# ESP32-S3 register map
Vendor: ESPRESSIF SYSTEMS (SHANGHAI) CO., LTD.; Series: ESP32 S-Series; File version: 22
CPU: Xtensa LX7 r0p0, little endian, no MPU, FPU, 0 interrupt priority bits
Address unit: 32 bits
Registers are 32-bit, read-write, reset 0x0 unless marked. A register's access mark holds for its fields unless they carry their own. Offsets are from the block's base; [hi:lo] are bit positions; {n}, {i} and the like mark numbered series.

## SPI1 — SPI (Serial Peripheral Interface) Controller 1
Base 0x60002000
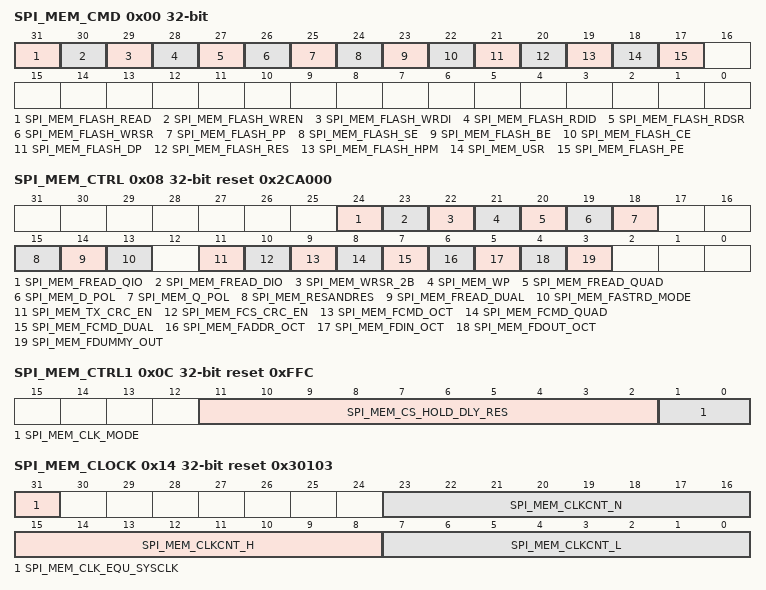
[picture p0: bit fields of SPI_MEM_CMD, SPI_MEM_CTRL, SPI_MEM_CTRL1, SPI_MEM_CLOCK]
0x00 SPI_MEM_CMD — SPI1 memory command register
  [31] SPI_MEM_FLASH_READ — Read flash enable. Read flash operation will be triggered when the bit is set. The bit will be cleared once the operation done. 1: enable 0: disable.
  [30] SPI_MEM_FLASH_WREN — Write flash enable. Write enable command will be sent when the bit is set. The bit will be cleared once the operation done. 1: enable 0: disable.
  [29] SPI_MEM_FLASH_WRDI — Write flash disable. Write disable command will be sent when the bit is set. The bit will be cleared once the operation done. 1: enable 0: disable.
  [28] SPI_MEM_FLASH_RDID — Read JEDEC ID . Read ID command will be sent when the bit is set. The bit will be cleared once the operation done. 1: enable 0: disable.
  [27] SPI_MEM_FLASH_RDSR — Read status register-1. Read status operation will be triggered when the bit is set. The bit will be cleared once the operation done.1: enable 0: disable.
  [26] SPI_MEM_FLASH_WRSR — Write status register enable. Write status operation will be triggered when the bit is set. The bit will be cleared once the operation done.1: enable 0: disable.
  [25] SPI_MEM_FLASH_PP — Page program enable(1 byte ~64 bytes data to be programmed). Page program operation will be triggered when the bit is set. The bit will be cleared once the operation done .1: enable 0: disable.
  [24] SPI_MEM_FLASH_SE — Sector erase enable(4KB). Sector erase operation will be triggered when the bit is set. The bit will be cleared once the operation done.1: enable 0: disable.
  [23] SPI_MEM_FLASH_BE — Block erase enable(32KB) . Block erase operation will be triggered when the bit is set. The bit will be cleared once the operation done.1: enable 0: disable.
  [22] SPI_MEM_FLASH_CE — Chip erase enable. Chip erase operation will be triggered when the bit is set. The bit will be cleared once the operation done.1: enable 0: disable.
  [21] SPI_MEM_FLASH_DP — Drive Flash into power down. An operation will be triggered when the bit is set. The bit will be cleared once the operation done.1: enable 0: disable.
  [20] SPI_MEM_FLASH_RES — This bit combined with SPI_MEM_RESANDRES bit releases Flash from the power-down state or high performance mode and obtains the devices ID. The bit will be cleared once the operation done.1: enable 0: disable.
  [19] SPI_MEM_FLASH_HPM — Drive Flash into high performance mode. The bit will be cleared once the operation done.1: enable 0: disable.
  [18] SPI_MEM_USR — User define command enable. An operation will be triggered when the bit is set. The bit will be cleared once the operation done.1: enable 0: disable.
  [17] SPI_MEM_FLASH_PE — In user mode, it is set to indicate that program/erase operation will be triggered. The bit is combined with SPI_MEM_USR bit. The bit will be cleared once the operation done.1: enable 0: disable.
0x04 SPI_MEM_ADDR — SPI1 address register
  [31:0] SPI_MEM_USR_ADDR_VALUE — In user mode, it is the memory address. other then the bit0-bit23 is the memory address, the bit24-bit31 are the byte length of a transfer.
0x08 SPI_MEM_CTRL reset 0x2CA000 — SPI1 control register
  [24] SPI_MEM_FREAD_QIO — In hardware 0xEB read operation, ADDR phase and DIN phase apply 4 signals(4-bit-mode). 1: enable 0: disable.
  [23] SPI_MEM_FREAD_DIO — In hardware 0xBB read operation, ADDR phase and DIN phase apply 2 signals(2-bit-mode). 1: enable 0: disable.
  [22] SPI_MEM_WRSR_2B — Two bytes data will be written to status register when it is set. 1: enable 0: disable.
  [21] SPI_MEM_WP — Write protect signal output when SPI is idle. 1: output high, 0: output low.
  [20] SPI_MEM_FREAD_QUAD — In hardware 0x6B read operation, DIN phase apply 4 signals(4-bit-mode). 1: enable 0: disable.
  [19] SPI_MEM_D_POL — The bit is used to set MOSI line polarity, 1: high 0, low
  [18] SPI_MEM_Q_POL — The bit is used to set MISO line polarity, 1: high 0, low
  [15] SPI_MEM_RESANDRES — The Device ID is read out to SPI_MEM_RD_STATUS register, this bit combine with spi_mem_flash_res bit. 1: enable 0: disable.
  [14] SPI_MEM_FREAD_DUAL — In hardware 0x3B read operation, DIN phase apply 2 signals. 1: enable 0: disable.
  [13] SPI_MEM_FASTRD_MODE — This bit should be set when SPI_MEM_FREAD_QIO, SPI_MEM_FREAD_DIO, SPI_MEM_FREAD_QUAD or SPI_MEM_FREAD_DUAL is set.
  [11] SPI_MEM_TX_CRC_EN — For SPI1, enable crc32 when writing encrypted data to flash. 1: enable 0:disable
  [10] SPI_MEM_FCS_CRC_EN — For SPI1, initialize crc32 module before writing encrypted data to flash. Active low.
  [9] SPI_MEM_FCMD_OCT — Set this bit to enable 8-bit-mode(8-bm) in CMD phase.
  [8] SPI_MEM_FCMD_QUAD — Set this bit to enable 4-bit-mode(4-bm) in CMD phase.
  [7] SPI_MEM_FCMD_DUAL — Set this bit to enable 2-bit-mode(2-bm) in CMD phase.
  [6] SPI_MEM_FADDR_OCT — Set this bit to enable 8-bit-mode(8-bm) in ADDR phase.
  [5] SPI_MEM_FDIN_OCT — Set this bit to enable 8-bit-mode(8-bm) in DIN phase.
  [4] SPI_MEM_FDOUT_OCT — Set this bit to enable 8-bit-mode(8-bm) in DOUT phase.
  [3] SPI_MEM_FDUMMY_OUT — In the DUMMY phase the signal level of SPI bus is output by the SPI0 controller.
0x0C SPI_MEM_CTRL1 reset 0xFFC — SPI1 control1 register
  [11:2] SPI_MEM_CS_HOLD_DLY_RES — After RES/DP/HPM/PES/PER command is sent, SPI1 may waits (SPI_MEM_CS_HOLD_DELAY_RES[9:0] * 4 or * 256) SPI_CLK cycles.
  [1:0] SPI_MEM_CLK_MODE — SPI Bus clock (SPI_CLK) mode bits. 0: SPI Bus clock (SPI_CLK) is off when CS inactive 1: SPI_CLK is delayed one cycle after SPI_CS inactive 2: SPI_CLK is delayed two cycles after SPI_CS inactive 3: SPI_CLK is always on.
0x10 SPI_MEM_CTRL2 — SPI1 control2 register
  [31] SPI_MEM_SYNC_RESET — The FSM will be reset.
0x14 SPI_MEM_CLOCK reset 0x30103 — SPI_CLK clock division register when SPI1 accesses to flash or Ext_RAM.
  [31] SPI_MEM_CLK_EQU_SYSCLK — When SPI1 access to flash or Ext_RAM, set this bit in 1-division mode, f_SPI_CLK = f_MSPI_CORE_CLK.
  [23:16] SPI_MEM_CLKCNT_N — When SPI1 accesses to flash or Ext_RAM, f_SPI_CLK = f_MSPI_CORE_CLK/(SPI_MEM_CLKCNT_N+1)
  [15:8] SPI_MEM_CLKCNT_H — It must be a floor value of ((SPI_MEM_CLKCNT_N+1)/2-1).
  [7:0] SPI_MEM_CLKCNT_L — It must equal to the value of SPI_MEM_CLKCNT_N.
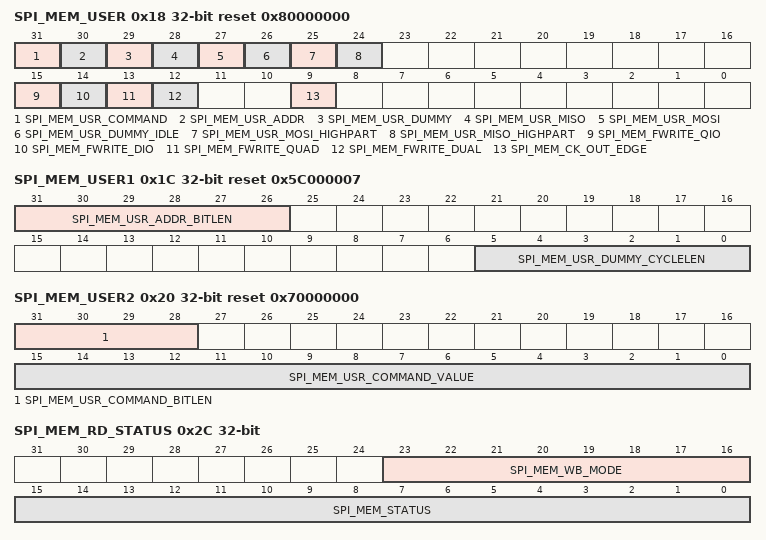
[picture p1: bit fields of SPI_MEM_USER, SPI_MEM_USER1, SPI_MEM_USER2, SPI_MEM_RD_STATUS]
0x18 SPI_MEM_USER reset 0x80000000 — SPI1 user register.
  [31] SPI_MEM_USR_COMMAND — Set this bit to enable enable the CMD phase of an operation.
  [30] SPI_MEM_USR_ADDR — Set this bit to enable enable the ADDR phase of an operation.
  [29] SPI_MEM_USR_DUMMY — Set this bit to enable enable the DUMMY phase of an operation.
  [28] SPI_MEM_USR_MISO — Set this bit to enable enable the DIN phase of a read-data operation.
  [27] SPI_MEM_USR_MOSI — Set this bit to enable the DOUT phase of an write-data operation.
  [26] SPI_MEM_USR_DUMMY_IDLE — SPI_CLK is disabled(No clock edges) in DUMMY phase when the bit is enable.
  [25] SPI_MEM_USR_MOSI_HIGHPART — DOUT phase only access to high-part of the buffer SPI_MEM_W8_REG~SPI_MEM_W15_REG. 1: enable 0: disable.
  [24] SPI_MEM_USR_MISO_HIGHPART — DIN phase only access to high-part of the buffer SPI_MEM_W8_REG~SPI_MEM_W15_REG. 1: enable 0: disable.
  [15] SPI_MEM_FWRITE_QIO — Set this bit to enable 4-bit-mode(4-bm) in ADDR and DOUT phase in SPI1 write operation.
  [14] SPI_MEM_FWRITE_DIO — Set this bit to enable 2-bm in ADDR and DOUT phase in SPI1 write operation.
  [13] SPI_MEM_FWRITE_QUAD — Set this bit to enable 4-bm in DOUT phase in SPI1 write operation.
  [12] SPI_MEM_FWRITE_DUAL — Set this bit to enable 2-bm in DOUT phase in SPI1 write operation.
  [9] SPI_MEM_CK_OUT_EDGE — This bit, combined with SPI_MEM_CK_IDLE_EDGE bit, is used to change the clock mode 0~3 of SPI_CLK.
0x1C SPI_MEM_USER1 reset 0x5C000007 — SPI1 user1 register.
  [31:26] SPI_MEM_USR_ADDR_BITLEN — The length in bits of ADDR phase. The register value shall be (bit_num-1).
  [5:0] SPI_MEM_USR_DUMMY_CYCLELEN — The SPI_CLK cycle length minus 1 of DUMMY phase.
0x20 SPI_MEM_USER2 reset 0x70000000 — SPI1 user2 register.
  [31:28] SPI_MEM_USR_COMMAND_BITLEN — The length in bits of CMD phase. The register value shall be (bit_num-1)
  [15:0] SPI_MEM_USR_COMMAND_VALUE — The value of user defined(USR) command.
0x24 SPI_MEM_MOSI_DLEN — SPI1 write-data bit length register.
  [9:0] SPI_MEM_USR_MOSI_DBITLEN — The length in bits of DOUT phase. The register value shall be (bit_num-1).
0x28 SPI_MEM_MISO_DLEN — SPI1 read-data bit length register.
  [9:0] SPI_MEM_USR_MISO_DBITLEN — The length in bits of DIN phase. The register value shall be (bit_num-1).
0x2C SPI_MEM_RD_STATUS — SPI1 read control register.
  [23:16] SPI_MEM_WB_MODE — Mode bits in the flash fast read mode it is combined with SPI_MEM_FASTRD_MODE bit.
  [15:0] SPI_MEM_STATUS — The value is stored when set SPI_MEM_FLASH_RDSR bit and SPI_MEM_FLASH_RES bit.
0x30 SPI_MEM_EXT_ADDR — SPI1 extended address register.
  [31:0] SPI_MEM_EXT_ADDR — The register are the higher 32bits in the 64 bits address mode.
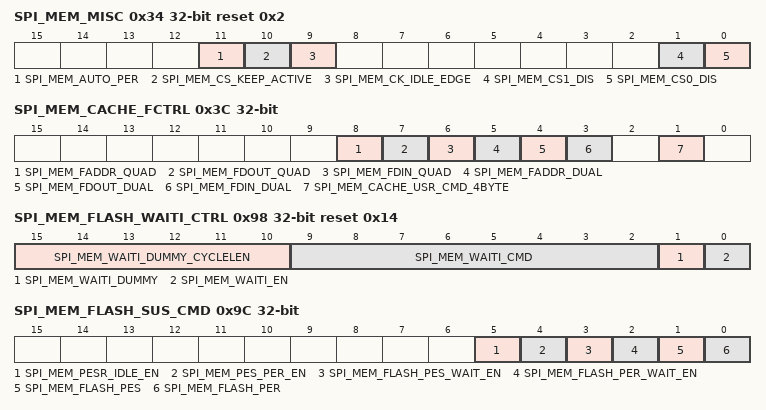
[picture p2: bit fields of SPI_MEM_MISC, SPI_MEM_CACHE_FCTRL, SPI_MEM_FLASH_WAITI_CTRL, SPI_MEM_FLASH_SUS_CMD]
0x34 SPI_MEM_MISC reset 0x2 — SPI1 misc register.
  [11] SPI_MEM_AUTO_PER — Set this bit to enable auto PER function. Hardware will sent out PER command if PES command is sent.
  [10] SPI_MEM_CS_KEEP_ACTIVE — SPI_CS line keep low when the bit is set.
  [9] SPI_MEM_CK_IDLE_EDGE — 1: SPI_CLK line is high when MSPI is idle. 0: SPI_CLK line is low when MSPI is idle.
  [1] SPI_MEM_CS1_DIS — Set this bit to raise high SPI_CS1 pin, which means that the SPI device(Ext_RAM) connected to SPI_CS1 is in low level when SPI1 transfer starts.
  [0] SPI_MEM_CS0_DIS — Set this bit to raise high SPI_CS pin, which means that the SPI device(flash) connected to SPI_CS is in low level when SPI1 transfer starts.
0x38 SPI_MEM_TX_CRC ro reset 0xFFFFFFFF — SPI1 CRC data register.
  [31:0] DATA — For SPI1, the value of crc32.
0x3C SPI_MEM_CACHE_FCTRL — SPI1 bit mode control register.
  [8] SPI_MEM_FADDR_QUAD — When SPI1 accesses to flash or Ext_RAM, set this bit to enable 4-bm in ADDR phase.
  [7] SPI_MEM_FDOUT_QUAD — When SPI1 accesses to flash or Ext_RAM, set this bit to enable 4-bm in DOUT phase.
  [6] SPI_MEM_FDIN_QUAD — When SPI1 accesses to flash or Ext_RAM, set this bit to enable 4-bm in DIN phase.
  [5] SPI_MEM_FADDR_DUAL — When SPI1 accesses to flash or Ext_RAM, set this bit to enable 2-bm in ADDR phase.
  [4] SPI_MEM_FDOUT_DUAL — When SPI1 accesses to flash or Ext_RAM, set this bit to enable 2-bm in DOUT phase.
  [3] SPI_MEM_FDIN_DUAL — When SPI1 accesses to flash or Ext_RAM, set this bit to enable 2-bm in DIN phase.
  [1] SPI_MEM_CACHE_USR_CMD_4BYTE — Set this bit to enable SPI1 transfer with 32 bits address. The value of SPI_MEM_USR_ADDR_BITLEN should be 31.
0x54 SPI_MEM_FSM ro — SPI1 state machine(FSM) status register.
  [2:0] SPI_MEM_ST — The status of SPI1 state machine. 0: idle state(IDLE), 1: preparation state(PREP), 2: send command state(CMD), 3: send address state(ADDR), 4: red data state(DIN), 5:write data state(DOUT), 6: wait state(DUMMY), 7: done state(DONE).
{0x58+4i} SPI_MEM_W{i} (i=0..15) — SPI1 memory data buffer{i}
  [31:0] SPI_MEM_BUF{i} — data buffer
0x98 SPI_MEM_FLASH_WAITI_CTRL reset 0x14 — SPI1 wait idle control register
  [15:10] SPI_MEM_WAITI_DUMMY_CYCLELEN — The dummy cycle length when wait flash idle(RDSR).
  [9:2] SPI_MEM_WAITI_CMD — The command value of auto wait flash idle transfer(RDSR).
  [1] SPI_MEM_WAITI_DUMMY — Set this bit to enable DUMMY phase in auto wait flash idle transfer(RDSR).
  [0] SPI_MEM_WAITI_EN — Set this bit to enable auto-waiting flash idle operation when PP/SE/BE/CE/WRSR/PES command is sent.
0x9C SPI_MEM_FLASH_SUS_CMD — SPI1 flash suspend control register
  [5] SPI_MEM_PESR_IDLE_EN — 1: Separate PER flash wait idle and PES flash wait idle. 0: Not separate.
  [4] SPI_MEM_PES_PER_EN — Set this bit to enable PES transfer trigger PES transfer option.
  [3] SPI_MEM_FLASH_PES_WAIT_EN — Set this bit to add delay time after program erase suspend(PES) command is sent.
  [2] SPI_MEM_FLASH_PER_WAIT_EN — Set this bit to add delay time after program erase resume(PER) is sent.
  [1] SPI_MEM_FLASH_PES — program erase suspend bit, program erase suspend operation will be triggered when the bit is set. The bit will be cleared once the operation done.1: enable 0: disable.
  [0] SPI_MEM_FLASH_PER — program erase resume bit, program erase suspend operation will be triggered when the bit is set. The bit will be cleared once the operation done.1: enable 0: disable.
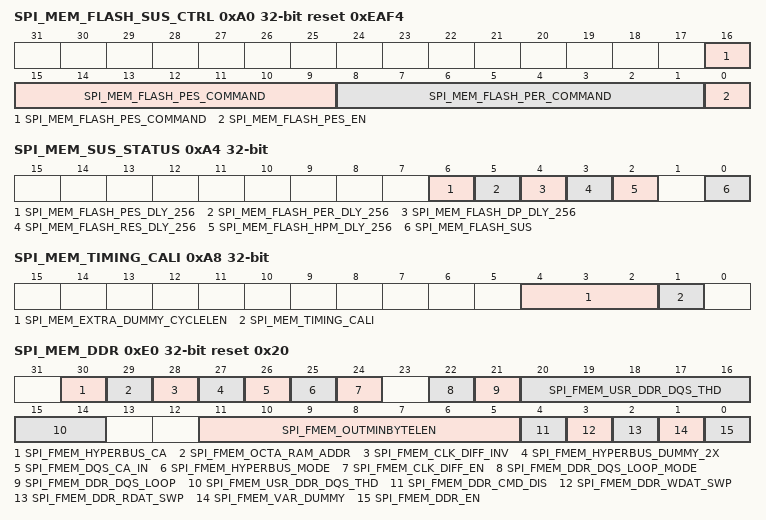
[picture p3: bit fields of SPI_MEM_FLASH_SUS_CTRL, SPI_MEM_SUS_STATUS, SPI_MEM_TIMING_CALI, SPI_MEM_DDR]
0xA0 SPI_MEM_FLASH_SUS_CTRL reset 0xEAF4 — SPI1 flash suspend command register
  [16:9] SPI_MEM_FLASH_PES_COMMAND — Program/Erase suspend command value.
  [8:1] SPI_MEM_FLASH_PER_COMMAND — Program/Erase resume command value.
  [0] SPI_MEM_FLASH_PES_EN — Set this bit to enable auto-suspend function.
0xA4 SPI_MEM_SUS_STATUS — SPI1 flash suspend status register
  [6] SPI_MEM_FLASH_PES_DLY_256 — Valid when SPI_MEM_FLASH_PES_WAIT_EN is 1. 1: SPI1 waits (SPI_MEM_CS_HOLD_DELAY_RES[9:0] * 256) SPI_CLK cycles after PES command is sent. 0: SPI1 waits (SPI_MEM_CS_HOLD_DELAY_RES[9:0] * 4) SPI_CLK cycles after PES command is sent.
  [5] SPI_MEM_FLASH_PER_DLY_256 — Valid when SPI_MEM_FLASH_PER_WAIT_EN is 1. 1: SPI1 waits (SPI_MEM_CS_HOLD_DELAY_RES[9:0] * 256) SPI_CLK cycles after PER command is sent. 0: SPI1 waits (SPI_MEM_CS_HOLD_DELAY_RES[9:0] * 4) SPI_CLK cycles after PER command is sent.
  [4] SPI_MEM_FLASH_DP_DLY_256 — 1: SPI1 waits (SPI_MEM_CS_HOLD_DELAY_RES[9:0] * 256) SPI_CLK cycles after DP command is sent. 0: SPI1 waits (SPI_MEM_CS_HOLD_DELAY_RES[9:0] * 4) SPI_CLK cycles after DP command is sent.
  [3] SPI_MEM_FLASH_RES_DLY_256 — 1: SPI1 waits (SPI_MEM_CS_HOLD_DELAY_RES[9:0] * 256) SPI_CLK cycles after RES command is sent. 0: SPI1 waits (SPI_MEM_CS_HOLD_DELAY_RES[9:0] * 4) SPI_CLK cycles after RES command is sent.
  [2] SPI_MEM_FLASH_HPM_DLY_256 — 1: SPI1 waits (SPI_MEM_CS_HOLD_DELAY_RES[9:0] * 256) SPI_CLK cycles after HPM command is sent. 0: SPI1 waits (SPI_MEM_CS_HOLD_DELAY_RES[9:0] * 4) SPI_CLK cycles after HPM command is sent.
  [0] SPI_MEM_FLASH_SUS — The status of flash suspend. This bit is set when PES command is sent, and cleared when PER is sent. Only used in SPI1.
0xA8 SPI_MEM_TIMING_CALI — SPI1 timing compensation register when accesses to flash or Ext_RAM.
  [4:2] SPI_MEM_EXTRA_DUMMY_CYCLELEN — Extra SPI_CLK cycles added in DUMMY phase for timing compensation. Active when SPI_MEM_TIMING_CALI bit is set.
  [1] SPI_MEM_TIMING_CALI — Set this bit to add extra SPI_CLK cycles in DUMMY phase for all reading operations.
0xE0 SPI_MEM_DDR reset 0x20 — SPI1 DDR control register
  [30] SPI_FMEM_HYPERBUS_CA — Set this bit to enable HyperRAM address out when accesses to flash, which means ADDR_OUT[31:0] = {spi_usr_addr_value[19:4], 13'd0, spi_usr_addr_value[3:1]}.
  [29] SPI_FMEM_OCTA_RAM_ADDR — Set this bit to enable octa_ram address out when accesses to flash, which means ADDR_OUT[31:0] = {spi_usr_addr_value[25:4], 6'd0, spi_usr_addr_value[3:1], 1'b0}.
  [28] SPI_FMEM_CLK_DIFF_INV — Set this bit to invert SPI_DIFF when accesses to flash. .
  [27] SPI_FMEM_HYPERBUS_DUMMY_2X — Set this bit to enable the vary dummy function in SPI HyperBus mode, when SPI0 accesses flash or SPI1 accesses flash or sram.
  [26] SPI_FMEM_DQS_CA_IN — Set this bit to enable the input of SPI_DQS signal in SPI phases of CMD and ADDR.
  [25] SPI_FMEM_HYPERBUS_MODE — Set this bit to enable the SPI HyperBus mode.
  [24] SPI_FMEM_CLK_DIFF_EN — Set this bit to enable the differential SPI_CLK#.
  [22] SPI_FMEM_DDR_DQS_LOOP_MODE — When SPI_FMEM_DDR_DQS_LOOP and SPI_FMEM_DDR_EN are set, 1: Use internal SPI_CLK as data strobe. 0: Use internal ~SPI_CLK as data strobe. Otherwise this bit is not active.
  [21] SPI_FMEM_DDR_DQS_LOOP — 1: Use internal signal as data strobe, the strobe can not be delayed by input timing module. 0: Use input SPI_DQS signal from PAD as data strobe, the strobe can be delayed by input timing module
  [20:14] SPI_FMEM_USR_DDR_DQS_THD — The delay number of data strobe which from memory based on SPI_CLK.
  [11:5] SPI_FMEM_OUTMINBYTELEN — It is the minimum output data length in the panda device.
  [4] SPI_FMEM_DDR_CMD_DIS — the bit is used to disable dual edge in command phase when DDR mode.
  [3] SPI_FMEM_DDR_WDAT_SWP — Set the bit to reorder TX data of the word in DDR mode.
  [2] SPI_FMEM_DDR_RDAT_SWP — Set the bit to reorder RX data of the word in DDR mode.
  [1] SPI_FMEM_VAR_DUMMY — Set the bit to enable variable dummy cycle in DDRmode.
  [0] SPI_FMEM_DDR_EN — 1: in DDR mode, 0: in SDR mode.
0xE8 SPI_MEM_CLOCK_GATE reset 0x1 — SPI1 clk_gate register
  [0] SPI_MEM_CLK_EN — Register clock gate enable signal. 1: Enable. 0: Disable.
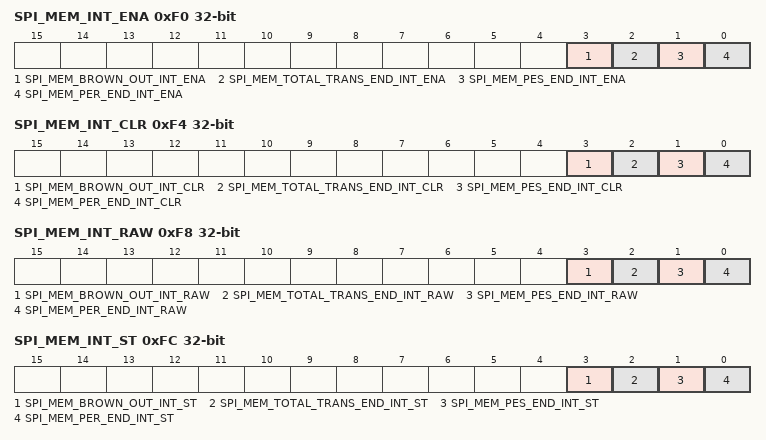
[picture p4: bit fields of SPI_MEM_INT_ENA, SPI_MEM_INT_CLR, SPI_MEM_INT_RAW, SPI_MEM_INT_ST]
0xF0 SPI_MEM_INT_ENA — SPI1 interrupt enable register
  [3] SPI_MEM_BROWN_OUT_INT_ENA — The enable bit for SPI_MEM_BROWN_OUT_INT interrupt.
  [2] SPI_MEM_TOTAL_TRANS_END_INT_ENA — The enable bit for SPI_MEM_TOTAL_TRANS_END_INT interrupt.
  [1] SPI_MEM_PES_END_INT_ENA — The enable bit for SPI_MEM_PES_END_INT interrupt.
  [0] SPI_MEM_PER_END_INT_ENA — The enable bit for SPI_MEM_PER_END_INT interrupt.
0xF4 SPI_MEM_INT_CLR wo — SPI1 interrupt clear register
  [3] SPI_MEM_BROWN_OUT_INT_CLR — The status bit for SPI_MEM_BROWN_OUT_INT interrupt.
  [2] SPI_MEM_TOTAL_TRANS_END_INT_CLR — The clear bit for SPI_MEM_TOTAL_TRANS_END_INT interrupt.
  [1] SPI_MEM_PES_END_INT_CLR — The clear bit for SPI_MEM_PES_END_INT interrupt.
  [0] SPI_MEM_PER_END_INT_CLR — The clear bit for SPI_MEM_PER_END_INT interrupt.
0xF8 SPI_MEM_INT_RAW — SPI1 interrupt raw register
  [3] SPI_MEM_BROWN_OUT_INT_RAW — The raw bit for SPI_MEM_BROWN_OUT_INT interrupt. 1: Triggered condition is that chip is loosing power and RTC module sends out brown out close flash request to SPI1. After SPI1 sends out suspend command to flash, this interrupt is triggered and MSPI returns to idle state. 0: Others.
  [2] SPI_MEM_TOTAL_TRANS_END_INT_RAW — The raw bit for SPI_MEM_TOTAL_TRANS_END_INT interrupt. 1: Triggered when SPI1 transfer is done and flash is already idle. When WRSR/PP/SE/BE/CE is sent and PES/PER command is sent, this bit is set when WRSR/PP/SE/BE/CE is success. 0: Others.
  [1] SPI_MEM_PES_END_INT_RAW — The raw bit for SPI_MEM_PES_END_INT interrupt.1: Triggered when Auto Suspend command (0x75) is sent and flash is suspended successfully. 0: Others.
  [0] SPI_MEM_PER_END_INT_RAW — The raw bit for SPI_MEM_PER_END_INT interrupt. 1: Triggered when Auto Resume command (0x7A) is sent and flash is resumed successfully. 0: Others.
0xFC SPI_MEM_INT_ST ro — SPI1 interrupt status register
  [3] SPI_MEM_BROWN_OUT_INT_ST — The status bit for SPI_MEM_BROWN_OUT_INT interrupt.
  [2] SPI_MEM_TOTAL_TRANS_END_INT_ST — The status bit for SPI_MEM_TOTAL_TRANS_END_INT interrupt.
  [1] SPI_MEM_PES_END_INT_ST — The status bit for SPI_MEM_PES_END_INT interrupt.
  [0] SPI_MEM_PER_END_INT_ST — The status bit for SPI_MEM_PER_END_INT interrupt.
0x3FC SPI_MEM_DATE reset 0x2101040 — SPI0 version control register
  [27:0] SPI_MEM_DATE — SPI register version.
